# N32L406 register map
Vendor: Nationstech Ltd.; File version: 1.0
Registers are 32-bit, read-write, reset 0x0 unless marked. A register's access mark holds for its fields unless they carry their own. Offsets are from the block's base; [hi:lo] are bit positions; {n}, {i} and the like mark numbered series.

## Control — System Control registers
Base 0xE000E008
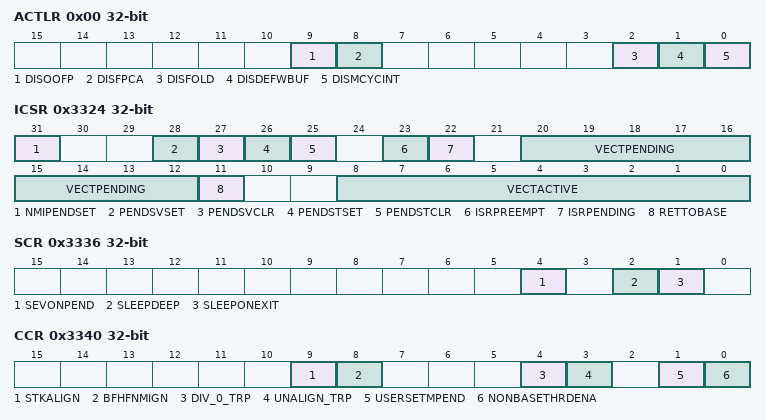
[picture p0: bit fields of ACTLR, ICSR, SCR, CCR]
0x00 ACTLR — Disables certain aspects of functionality within the processor
  [all] fields
    0=Enabled; 1=Disabled
  [9] DISOOFP — Disables floating point instructions completing out of order with respect to integer instructions
  [8] DISFPCA — Disable automatic update of CONTROL.FPCA
  [2] DISFOLD — Disables folding of IT instructions
  [1] DISDEFWBUF — Disables write buffer use during default memory map accesses
  [0] DISMCYCINT — Disables interruption of multi-cycle instructions
0x3324 ICSR — Provides software control of the NMI, PendSV, and SysTick exceptions, and provides interrupt status information
  [31] NMIPENDSET — Activates an NMI exception or reads back the current state
    0=Do_not_activate; 1=Activate_NMI_exception
  [28] PENDSVSET — Sets a pending PendSV interrupt or reads back the current state
    0=Do_not_set; 1=Set_pending
  [27] PENDSVCLR — Clears a pending PendSV interrupt
    0=Do_not_clear; 1=Clear_pending
  [26] PENDSTSET — Sets a pending SysTick or reads back the current state
    0=Do_not_set; 1=Set_pending
  [25] PENDSTCLR — Clears a pending SysTick, whether set here or by the timer hardware
    0=Do_not_clear; 1=Clear_pending
  [23] ISRPREEMPT — Indicates whether a pending exception will be serviced on exit from debug halt state
    0=Will_not_service; 1=Will_service_pending_exception
  [22] ISRPENDING — Indicates if an external configurable, NVIC generated, interrupt is pending
    0=Interrupt_not_pending; 1=Interrupt_pending
  [20:12] VECTPENDING — The exception number for the highest priority pending exception. 0 indicates no pending exceptions
  [11] RETTOBASE — In Handler mode, indicates whether there is an active exception other than the exception indicated by the current value of the IPSR
    0=Active_exception; 1=No_Active_Exception
  [8:0] VECTACTIVE — The exception number for the current executing exception
0x3328 VTOR — Holds the vector table address
  [29] TBLBASE — Determines whether the vector table is in the code or SRAM memory region
    0=CODE; 1=SRAM
  [31:7] TBLOFF — Bits [31:7] of the vector table address
0x3332 AIRCR — Sets or returns interrupt control data
  [31:16] VECTKEY — Vector Key
  [31:16] VECTKEYSTAT
  [15] ENDIANNESS — Indicates the memory system data endianness
    0=Little_endian; 1=Big_endian
  [10:8] PRIGROUP — Priority grouping, indicates the binary point position.
  [2] SYSRESETREQ — System Reset Request
    0=Do_not_request_reset; 1=Request_reset
  [1] VECTCLRACTIVE — Clears all active state information for fixed and configurable exceptions
    0=Do_not_clear; 1=Clear_state_information
0x3336 SCR — Sets or returns system control data
  [4] SEVONPEND — Determines whether an interrupt transition from inactive state to pending state is a wakeup event
    0=Not_wakeup; 1=Wakeup
  [2] SLEEPDEEP — Hint indicating that waking from sleep might take longer
    0=Not_deep_sleep; 1=Deep_sleep
  [1] SLEEPONEXIT — whether, on an exit from an ISR that returns to the base level of execution priority, the processor enters a sleep state
    0=Do_not_enter; 1=Enter
0x3340 CCR — Configuration and Control
  [9] STKALIGN — Determines whether the exception entry sequence guarantees 8-byte stack frame alignment, adjusting the SP if necessary before saving state
    0=_4_Byte; 1=_8_Byte
  [8] BFHFNMIGN — Determines the effect of precise data access faults on handlers running at priority -1 or priority -2
    0=Fault; 1=Ignore
  [4] DIV_0_TRP — Controls the trap on divide by 0
    0=Disabled; 1=Enabled
  [3] UNALIGN_TRP — Controls the trapping of unaligned word or halfword accesses
    0=Disabled; 1=Enabled
  [1] USERSETMPEND — Controls whether unprivileged software can access the STIR
    0=Disabled; 1=Enabled
  [0] NONBASETHRDENA — Controls whether the processor can enter Thread mode at an execution priority level other than base level
    0=Disabled; 1=Enabled
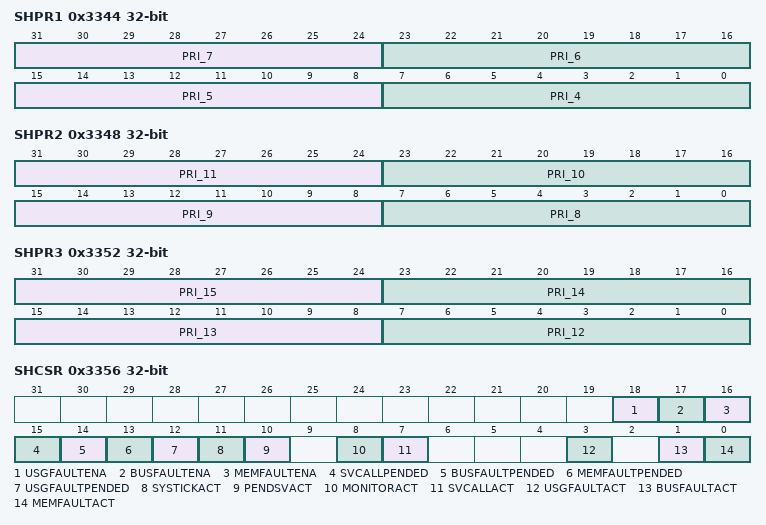
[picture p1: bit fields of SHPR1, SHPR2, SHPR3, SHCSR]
0x3344 SHPR1 — Sets or returns priority for system handlers 4-7
  [31:24] PRI_7 — Priority of system handler 7
  [23:16] PRI_6 — Priority of system handler 6, UsageFault
  [15:8] PRI_5 — Priority of system handler 5, BusFault
  [7:0] PRI_4 — Priority of system handler 4, MemManage
0x3348 SHPR2 — Sets or returns priority for system handlers 8-11
  [31:24] PRI_11 — Priority of system handler 11, SVCall
  [23:16] PRI_10 — Priority of system handler 10
  [15:8] PRI_9 — Priority of system handler 9
  [7:0] PRI_8 — Priority of system handler 8
0x3352 SHPR3 — Sets or returns priority for system handlers 12-15
  [31:24] PRI_15 — Priority of system handler 15, SysTick
  [23:16] PRI_14 — Priority of system handler 14, PendSV
  [15:8] PRI_13 — Priority of system handler 13
  [7:0] PRI_12 — Priority of system handler 4, DebugMonitor
0x3356 SHCSR — Controls and provides the active and pending status of system exceptions
  [18] USGFAULTENA — Enable UsageFault
    0=Disabled; 1=Enabled
  [17] BUSFAULTENA — Enable BusFault
    0=Disabled; 1=Enabled
  [16] MEMFAULTENA — Enable MemManage fault
    0=Disabled; 1=Enabled
  [15] SVCALLPENDED — SVCall pending
    0=Not_pending; 1=Pending
  [14] BUSFAULTPENDED — BusFault pending
    0=Not_pending; 1=Pending
  [13] MEMFAULTPENDED — MemManage pending
    0=Not_pending; 1=Pending
  [12] USGFAULTPENDED — UsageFault pending
    0=Not_pending; 1=Pending
  [11] SYSTICKACT — SysTick active
    0=Not_active; 1=Active
  [10] PENDSVACT — PendSV active
    0=Not_active; 1=Active
  [8] MONITORACT — Monitor active
    0=Not_active; 1=Active
  [7] SVCALLACT — SVCall active
    0=Not_active; 1=Active
  [3] USGFAULTACT — UsageFault active
    0=Not_active; 1=Active
  [1] BUSFAULTACT — BusFault active
    0=Not_active; 1=Active
  [0] MEMFAULTACT — MemManage active
    0=Not_active; 1=Active
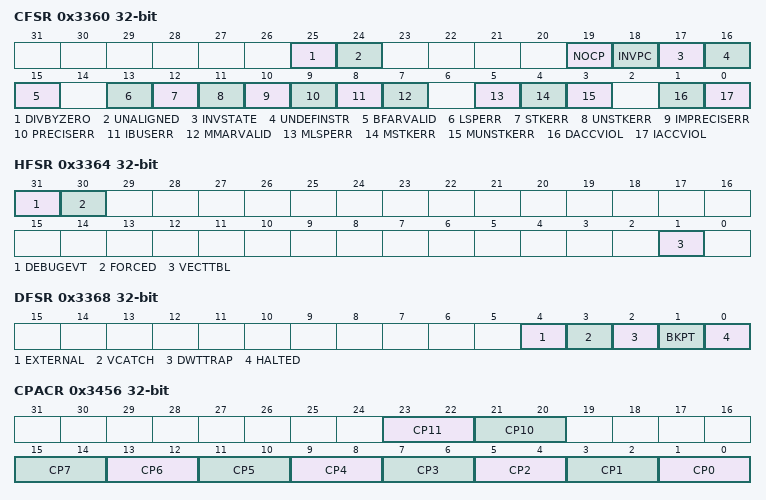
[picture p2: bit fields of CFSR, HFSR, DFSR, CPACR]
0x3360 CFSR — Contains the three Configurable Fault Status Registers MMFSR, BFSR, UFSR
  [25] DIVBYZERO — Divide by zero error
    0=Not_occurred; 1=Occurred
  [24] UNALIGNED — Unaligned access error
    0=Not_occurred; 1=Occurred
  [19] NOCP — Coprocessor access error
    0=Not_occurred; 1=Occurred
  [18] INVPC — Integrity check error on EXC_RETURN
    0=Not_occurred; 1=Occurred
  [17] INVSTATE — Instruction executed with invalid EPSR.T or EPSR.IT field
    0=Not_occurred; 1=Occurred
  [16] UNDEFINSTR — Processor has attempted to execute an undefined instruction.
    0=Not_occurred; 1=Occurred
  [15] BFARVALID — BFAR has valid contents
    0=Not_valid; 1=Valid
  [13] LSPERR — Bus fault during FP lazy state preservation
    0=Not_occurred; 1=Occurred
  [12] STKERR — Derived bus fault on exception entry
    0=Not_occurred; 1=Occurred
  [11] UNSTKERR — Derived bus fault on exception return
    0=Not_occurred; 1=Occurred
  [10] IMPRECISERR — Imprecise data access error
    0=Not_occurred; 1=Occurred
  [9] PRECISERR — Precise data access error
    0=Not_occurred; 1=Occurred
  [8] IBUSERR — Bus fault on an instruction prefetch
    0=Not_occurred; 1=Occurred
  [7] MMARVALID — MMAR has valid contents
    0=Not_valid; 1=Valid
  [5] MLSPERR — MemManage fault during FP lazy state preservation
    0=Not_occurred; 1=Occurred
  [4] MSTKERR — Derived MemManage fault on exception entry
    0=Not_occurred; 1=Occurred
  [3] MUNSTKERR — Derived MemManage fault on exception return
    0=Not_occurred; 1=Occurred
  [1] DACCVIOL — Data access violation. The MMAR shows the data address that the load or store tried to access
    0=Not_occurred; 1=Occurred
  [0] IACCVIOL — MPU or Execute Never (XN) default memory map access violation on an instruction fetch
    0=Not_occurred; 1=Occurred
0x3364 HFSR — Shows the cause of any hard faults
  [all] fields
    0=Not_occurred; 1=Occurred
  [31] DEBUGEVT — Indicates a Debug event has occurred
  [30] FORCED — Indicates a fault with configurable priority has been escalated to a HardFault
  [1] VECTTBL — Indicates a fault has occurred because of a vector table read error on exception processing
0x3368 DFSR — Shows, at the top level, why a debug event occurred
  [4] EXTERNAL — Indicates a debug event generated because of the assertion of EDBGRQ
  [3] VCATCH — Indicates triggering of a Vector catch
  [2] DWTTRAP — Indicates a debug event generated by the DWT
  [1] BKPT — Indicates a debug event generated by BKPT instruction execution or a breakpoint match in FPB
  [0] HALTED — Indicates a debug event generated by C_HALT or C_STEP request or setting DEMCR.MON_STEP
0x3372 MMFAR — Shows the address of the memory location that caused an MMU fault
0x3376 BFAR — Shows the address associated with a precise data access fault
0x3380 AFSR — Latched version of the AUXFAULT inputs
0x3456 CPACR — Specifies the access privileges for coprocessors
  [all] fields
    0=Access_denied; 1=Privileged_mode_access_only; 3=Full_access
  [23:22] CP11 — Defines access permissions for the CP11 coprocessor.
  [21:20] CP10 — Defines access permissions for the CP10 coprocessor.
  [2n+1:2n] CP{n} (n=0..7) — Defines access permissions for the CP{n} coprocessor.
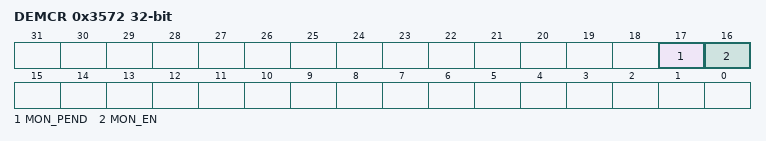
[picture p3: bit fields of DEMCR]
0x3572 DEMCR ro — Manages vector catch behaviour and DebugMonitor handling when debugging
  [17] MON_PEND — Sets or clears the pending state of the DebugMonitor exception
  [16] MON_EN — Enable the DebugMonitor exception
0x3832 STIR wo — Provides a mechanism for software to generate an interrupt
  [8:0] INTID — Indicates the interrupt to be triggered. The value written is (ExceptionNumber - 16)
